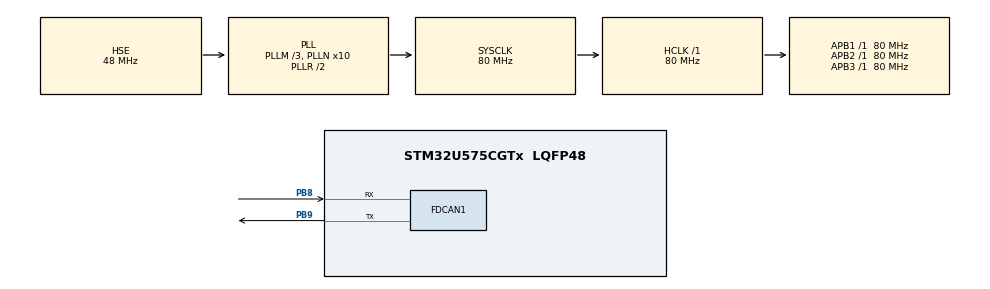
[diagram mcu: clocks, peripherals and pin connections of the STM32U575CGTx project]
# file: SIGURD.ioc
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CORTEX_M33_NS.userName=CORTEX_M33
FDCAN1.AutoRetransmission=ENABLE
FDCAN1.CalculateBaudRateNominal=500000
FDCAN1.CalculateTimeBitNominal=2000
FDCAN1.CalculateTimeQuantumNominal=12.5
FDCAN1.FrameFormat=FDCAN_FRAME_FD_NO_BRS
FDCAN1.NominalPrescaler=1
FDCAN1.NominalTimeSeg1=129
FDCAN1.NominalTimeSeg2=30
Mcu.Family=STM32U5
Mcu.Name=STM32U575CGTx
Mcu.Package=LQFP48
NVIC.FDCAN1_IT0_IRQn=true\:0\:0\:false\:false\:true\:true\:true\:true
NVIC.PriorityGroup=NVIC_PRIORITYGROUP_4
PA0.Signal=S_TIM2_CH1
PA1.Signal=S_TIM2_CH2
PA2.Signal=S_TIM2_CH3
PA6.Signal=S_TIM3_CH1
PB8.Mode=FDCAN_Activate
PB8.Signal=FDCAN1_RX
PB9.Mode=FDCAN_Activate
PB9.Signal=FDCAN1_TX
PH0-OSC_IN\ (PH0).Mode=HSE-External-Oscillator
PH0-OSC_IN\ (PH0).Signal=RCC_OSC_IN
PH1-OSC_OUT\ (PH1).Mode=HSE-External-Oscillator
PH1-OSC_OUT\ (PH1).Signal=RCC_OSC_OUT
ProjectManager.HeapSize=0x200
ProjectManager.StackSize=0x400
ProjectManager.TargetToolchain=STM32CubeIDE
RCC.ADCFreq_Value=16000000
RCC.AHBFreq_Value=80000000
RCC.APB1Freq_Value=80000000
RCC.APB1TimFreq_Value=80000000
RCC.APB2Freq_Value=80000000
RCC.APB2TimFreq_Value=80000000
RCC.APB3Freq_Value=80000000
RCC.CortexFreq_Value=80000000
RCC.EPOD_VALUE=48000000
RCC.HCLKFreq_Value=80000000
RCC.HSE_VALUE=48000000
RCC.HSI48_VALUE=48000000
RCC.HSI_VALUE=16000000
RCC.LSE_VALUE=32768
RCC.LSIDIV_VALUE=32000
RCC.MSI_VALUE=4000000
RCC.PLLFRACN=0
RCC.PLLM=3
RCC.PLLN=10
RCC.PLLSourceVirtual=RCC_PLLSOURCE_HSE
RCC.SYSCLKFreq_VALUE=80000000
RCC.SYSCLKSource=RCC_SYSCLKSOURCE_PLLCLK
RCC.USBFreq_Value=48000000
RCC.VCOOutputFreq_Value=160000000
SH.S_TIM2_CH1.0=TIM2_CH1
SH.S_TIM2_CH2.0=TIM2_CH2
SH.S_TIM2_CH3.0=TIM2_CH3
SH.S_TIM3_CH1.0=TIM3_CH1
TIM2.Channel-PWM\ Generation1\ No\ Output=TIM_CHANNEL_1
TIM2.Channel-PWM\ Generation2\ No\ Output=TIM_CHANNEL_2
TIM2.Channel-PWM\ Generation3\ No\ Output=TIM_CHANNEL_3
TIM2.PeriodNoDither=1000-1
TIM2.Prescaler=80-1
TIM3.Channel-PWM\ Generation1\ No\ Output=TIM_CHANNEL_1
TIM3.PeriodNoDither=20000-1
TIM3.Prescaler=80-1
VP_LPBAMQUEUE_VS_QUEUE.Mode=QUEUEMODE
VP_MEMORYMAP_VS_MEMORYMAP.Mode=CurAppReg
VP_PWR_VS_SECSignals.Mode=Security/Privilege
VP_TIM2_VS_no_output1.Mode=PWM Generation1 No Output
VP_TIM2_VS_no_output2.Mode=PWM Generation2 No Output
VP_TIM2_VS_no_output3.Mode=PWM Generation3 No Output
VP_TIM3_VS_no_output1.Mode=PWM Generation1 No Output
board=custom

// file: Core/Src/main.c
/* USER CODE BEGIN Header */
/**
  ******************************************************************************
  * @file           : main.c
  * @brief          : Main program body
  ******************************************************************************
  * @attention
  *
  * Copyright (c) 2025 STMicroelectronics.
  * All rights reserved.
  *
  * This software is licensed under terms that can be found in the LICENSE file
  * in the root directory of this software component.
  * If no LICENSE file comes with this software, it is provided AS-IS.
  *
  ******************************************************************************
  */
/* USER CODE END Header */
#include "main.h"

/* USER CODE BEGIN Includes */
#include <stdio.h>

/* USER CODE END Includes */

FDCAN_HandleTypeDef hfdcan1;

TIM_HandleTypeDef htim2;
TIM_HandleTypeDef htim3;

/* USER CODE BEGIN PV */

FDCAN_RxHeaderTypeDef RxHeader;
uint8_t RxData[8];
FDCAN_TxHeaderTypeDef TxHeader;
uint8_t TxData[8];

/* USER CODE END PV */

void SystemClock_Config(void);
static void MX_GPIO_Init(void);
static void MX_FDCAN1_Init(void);
static void MX_TIM3_Init(void);
static void MX_TIM2_Init(void);
/* USER CODE BEGIN PFP */

static void FDCAN_Config(void);
static void MOTOR_PWM(uint8_t Status);

/* USER CODE END PFP */

int main(void)
{

  /* MCU Configuration--------------------------------------------------------*/

  /* Reset of all peripherals, Initializes the Flash interface and the Systick. */
  HAL_Init();

  /* Configure the system clock */
  SystemClock_Config();

  /* Initialize all configured peripherals */
  MX_GPIO_Init();
  MX_FDCAN1_Init();
  MX_TIM3_Init();
  MX_TIM2_Init();
  /* USER CODE BEGIN 2 */

  FDCAN_Config();

  initMotor();

  /* USER CODE END 2 */

  /* Infinite loop */
  while (1)
  {

  }
}

void SystemClock_Config(void)
{
  RCC_OscInitTypeDef RCC_OscInitStruct = {0};
  RCC_ClkInitTypeDef RCC_ClkInitStruct = {0};

  /** Configure the main internal regulator output voltage
  */
  if (HAL_PWREx_ControlVoltageScaling(PWR_REGULATOR_VOLTAGE_SCALE2) != HAL_OK)
  {
    Error_Handler();
  }

  /** Initializes the CPU, AHB and APB buses clocks
  */
  RCC_OscInitStruct.OscillatorType = RCC_OSCILLATORTYPE_HSE;
  RCC_OscInitStruct.HSEState = RCC_HSE_ON;
  RCC_OscInitStruct.PLL.PLLState = RCC_PLL_ON;
  RCC_OscInitStruct.PLL.PLLSource = RCC_PLLSOURCE_HSE;
  RCC_OscInitStruct.PLL.PLLMBOOST = RCC_PLLMBOOST_DIV4;
  RCC_OscInitStruct.PLL.PLLM = 3;
  RCC_OscInitStruct.PLL.PLLN = 10;
  RCC_OscInitStruct.PLL.PLLP = 2;
  RCC_OscInitStruct.PLL.PLLQ = 2;
  RCC_OscInitStruct.PLL.PLLR = 2;
  RCC_OscInitStruct.PLL.PLLRGE = RCC_PLLVCIRANGE_1;
  RCC_OscInitStruct.PLL.PLLFRACN = 0;
  if (HAL_RCC_OscConfig(&RCC_OscInitStruct) != HAL_OK)
  {
    Error_Handler();
  }

  /** Initializes the CPU, AHB and APB buses clocks
  */
  RCC_ClkInitStruct.ClockType = RCC_CLOCKTYPE_HCLK|RCC_CLOCKTYPE_SYSCLK
                              |RCC_CLOCKTYPE_PCLK1|RCC_CLOCKTYPE_PCLK2
                              |RCC_CLOCKTYPE_PCLK3;
  RCC_ClkInitStruct.SYSCLKSource = RCC_SYSCLKSOURCE_PLLCLK;
  RCC_ClkInitStruct.AHBCLKDivider = RCC_SYSCLK_DIV1;
  RCC_ClkInitStruct.APB1CLKDivider = RCC_HCLK_DIV1;
  RCC_ClkInitStruct.APB2CLKDivider = RCC_HCLK_DIV1;
  RCC_ClkInitStruct.APB3CLKDivider = RCC_HCLK_DIV1;

  if (HAL_RCC_ClockConfig(&RCC_ClkInitStruct, FLASH_LATENCY_2) != HAL_OK)
  {
    Error_Handler();
  }
}

static void MX_FDCAN1_Init(void)
{

  hfdcan1.Instance = FDCAN1;
  hfdcan1.Init.ClockDivider = FDCAN_CLOCK_DIV1;
  hfdcan1.Init.FrameFormat = FDCAN_FRAME_FD_NO_BRS;
  hfdcan1.Init.Mode = FDCAN_MODE_NORMAL;
  hfdcan1.Init.AutoRetransmission = ENABLE;
  hfdcan1.Init.TransmitPause = DISABLE;
  hfdcan1.Init.ProtocolException = DISABLE;
  hfdcan1.Init.NominalPrescaler = 1;
  hfdcan1.Init.NominalSyncJumpWidth = 1;
  hfdcan1.Init.NominalTimeSeg1 = 129;
  hfdcan1.Init.NominalTimeSeg2 = 30;
  hfdcan1.Init.DataPrescaler = 1;
  hfdcan1.Init.DataSyncJumpWidth = 1;
  hfdcan1.Init.DataTimeSeg1 = 1;
  hfdcan1.Init.DataTimeSeg2 = 1;
  hfdcan1.Init.StdFiltersNbr = 0;
  hfdcan1.Init.ExtFiltersNbr = 0;
  hfdcan1.Init.TxFifoQueueMode = FDCAN_TX_FIFO_OPERATION;
  if (HAL_FDCAN_Init(&hfdcan1) != HAL_OK)
  {
    Error_Handler();
  }

}

static void MX_TIM2_Init(void)
{

  TIM_MasterConfigTypeDef sMasterConfig = {0};
  TIM_OC_InitTypeDef sConfigOC = {0};

  htim2.Instance = TIM2;
  htim2.Init.Prescaler = 80-1;
  htim2.Init.CounterMode = TIM_COUNTERMODE_UP;
  htim2.Init.Period = 999;
  htim2.Init.ClockDivision = TIM_CLOCKDIVISION_DIV1;
  htim2.Init.AutoReloadPreload = TIM_AUTORELOAD_PRELOAD_DISABLE;
  if (HAL_TIM_PWM_Init(&htim2) != HAL_OK)
  {
    Error_Handler();
  }
  sMasterConfig.MasterOutputTrigger = TIM_TRGO_RESET;
  sMasterConfig.MasterSlaveMode = TIM_MASTERSLAVEMODE_DISABLE;
  if (HAL_TIMEx_MasterConfigSynchronization(&htim2, &sMasterConfig) != HAL_OK)
  {
    Error_Handler();
  }
  sConfigOC.OCMode = TIM_OCMODE_PWM1;
  sConfigOC.Pulse = 0;
  sConfigOC.OCPolarity = TIM_OCPOLARITY_HIGH;
  sConfigOC.OCFastMode = TIM_OCFAST_DISABLE;
  if (HAL_TIM_PWM_ConfigChannel(&htim2, &sConfigOC, TIM_CHANNEL_1) != HAL_OK)
  {
    Error_Handler();
  }
  if (HAL_TIM_PWM_ConfigChannel(&htim2, &sConfigOC, TIM_CHANNEL_2) != HAL_OK)
  {
    Error_Handler();
  }
  if (HAL_TIM_PWM_ConfigChannel(&htim2, &sConfigOC, TIM_CHANNEL_3) != HAL_OK)
  {
    Error_Handler();
  }

}

static void MX_TIM3_Init(void)
{

  TIM_MasterConfigTypeDef sMasterConfig = {0};
  TIM_OC_InitTypeDef sConfigOC = {0};

  htim3.Instance = TIM3;
  htim3.Init.Prescaler = 80-1;
  htim3.Init.CounterMode = TIM_COUNTERMODE_UP;
  htim3.Init.Period = 19999;
  htim3.Init.ClockDivision = TIM_CLOCKDIVISION_DIV1;
  htim3.Init.AutoReloadPreload = TIM_AUTORELOAD_PRELOAD_DISABLE;
  if (HAL_TIM_PWM_Init(&htim3) != HAL_OK)
  {
    Error_Handler();
  }
  sMasterConfig.MasterOutputTrigger = TIM_TRGO_RESET;
  sMasterConfig.MasterSlaveMode = TIM_MASTERSLAVEMODE_DISABLE;
  if (HAL_TIMEx_MasterConfigSynchronization(&htim3, &sMasterConfig) != HAL_OK)
  {
    Error_Handler();
  }
  sConfigOC.OCMode = TIM_OCMODE_PWM1;
  sConfigOC.Pulse = 0;
  sConfigOC.OCPolarity = TIM_OCPOLARITY_HIGH;
  sConfigOC.OCFastMode = TIM_OCFAST_DISABLE;
  if (HAL_TIM_PWM_ConfigChannel(&htim3, &sConfigOC, TIM_CHANNEL_1) != HAL_OK)
  {
    Error_Handler();
  }

}

static void MX_GPIO_Init(void)
{

  /* GPIO Ports Clock Enable */
  __HAL_RCC_GPIOH_CLK_ENABLE();
  __HAL_RCC_GPIOA_CLK_ENABLE();
  __HAL_RCC_GPIOB_CLK_ENABLE();

}

/* USER CODE BEGIN 4 */

static void FDCAN_Config(void)
{
  FDCAN_FilterTypeDef sFilterConfig;

  /* Configure Rx filter */
  sFilterConfig.IdType = FDCAN_STANDARD_ID;
  sFilterConfig.FilterIndex = 0;
  sFilterConfig.FilterType = FDCAN_FILTER_RANGE;
  sFilterConfig.FilterConfig = FDCAN_FILTER_TO_RXFIFO0;
  sFilterConfig.FilterID1 = 0x696;
  sFilterConfig.FilterID2 = 0x699;
  if (HAL_FDCAN_ConfigFilter(&hfdcan1, &sFilterConfig) != HAL_OK)
  {
    Error_Handler();
  }

  /* Start the FDCAN module */
  if (HAL_FDCAN_Start(&hfdcan1) != HAL_OK)
  {
    Error_Handler();
  }

  if (HAL_FDCAN_ActivateNotification(&hfdcan1, FDCAN_IT_RX_FIFO0_NEW_MESSAGE, 0) != HAL_OK)
  {
    Error_Handler();
  }

  /* Prepare Tx Header */
  TxHeader.Identifier = 0x321;
  TxHeader.IdType = FDCAN_STANDARD_ID;
  TxHeader.TxFrameType = FDCAN_DATA_FRAME;
  TxHeader.DataLength = FDCAN_DLC_BYTES_2;
  TxHeader.ErrorStateIndicator = FDCAN_ESI_PASSIVE;
  TxHeader.BitRateSwitch = FDCAN_BRS_OFF;
  TxHeader.FDFormat = FDCAN_CLASSIC_CAN;
  TxHeader.TxEventFifoControl = FDCAN_NO_TX_EVENTS;
  TxHeader.MessageMarker = 0;
}

void HAL_FDCAN_RxFifo0Callback(FDCAN_HandleTypeDef *hfdcan, uint32_t RxFifo0ITs)
{
    if ((RxFifo0ITs & FDCAN_IT_RX_FIFO0_NEW_MESSAGE) != 0)
    {
        HAL_FDCAN_GetRxMessage(hfdcan, FDCAN_RX_FIFO0, &RxHeader, RxData);

        if (RxHeader.DataLength == FDCAN_DLC_BYTES_1 && RxData[0] == 1)
        {
            Motor_PWM(1); // ON
        }
        else if (RxHeader.DataLength == FDCAN_DLC_BYTES_1 && RxData[0] == 0)
        {
            Motor_PWM(0); // OFF
        }
    }
}

void Motor_PWM(uint8_t STATUS) {
	initMotor();
}

void initMotor() {
    TIM_HandleTypeDef *htim = &MOTOR_TIMER_HANDLE; // MOTOR_TIMER_HANDLE is a #defined variable
    setPWM(htim, MOTOR_TIMER_CHANNEL, 0.05); // Initial 5% duty cycle
    HAL_TIM_PWM_Start(htim, MOTOR_TIMER_CHANNEL); // Start PWM
    HAL_Delay(5000);
}

void setPWM(TIM_HandleTypeDef *timer_handle, uint32_t timer_channel, float duty) {
    uint32_t counter_period = __HAL_TIM_GET_AUTORELOAD(timer_handle); // Get the ARR value (number of ticks per period)
    uint32_t new_duty = duty * counter_period; // Calculate new duty value
    //__HAL_TIM_DISABLE(timer_handle);
    __HAL_TIM_SET_COMPARE(timer_handle, timer_channel, new_duty); // Set compare value to new duty
}

void setMotorSpeed(float throttle) { // if statements to restrict duty between 0.05f and 0.1f

    TIM_HandleTypeDef *htim = &MOTOR_TIMER_HANDLE;
    float duty = throttle*0.05f + 0.05f;
    setPWM(htim, MOTOR_TIMER_CHANNEL, duty);
    status.setMotorSpeed(throttle);
}

/* USER CODE END 4 */

void Error_Handler(void)
{
  __disable_irq();
  while (1)
  {
  }
}
